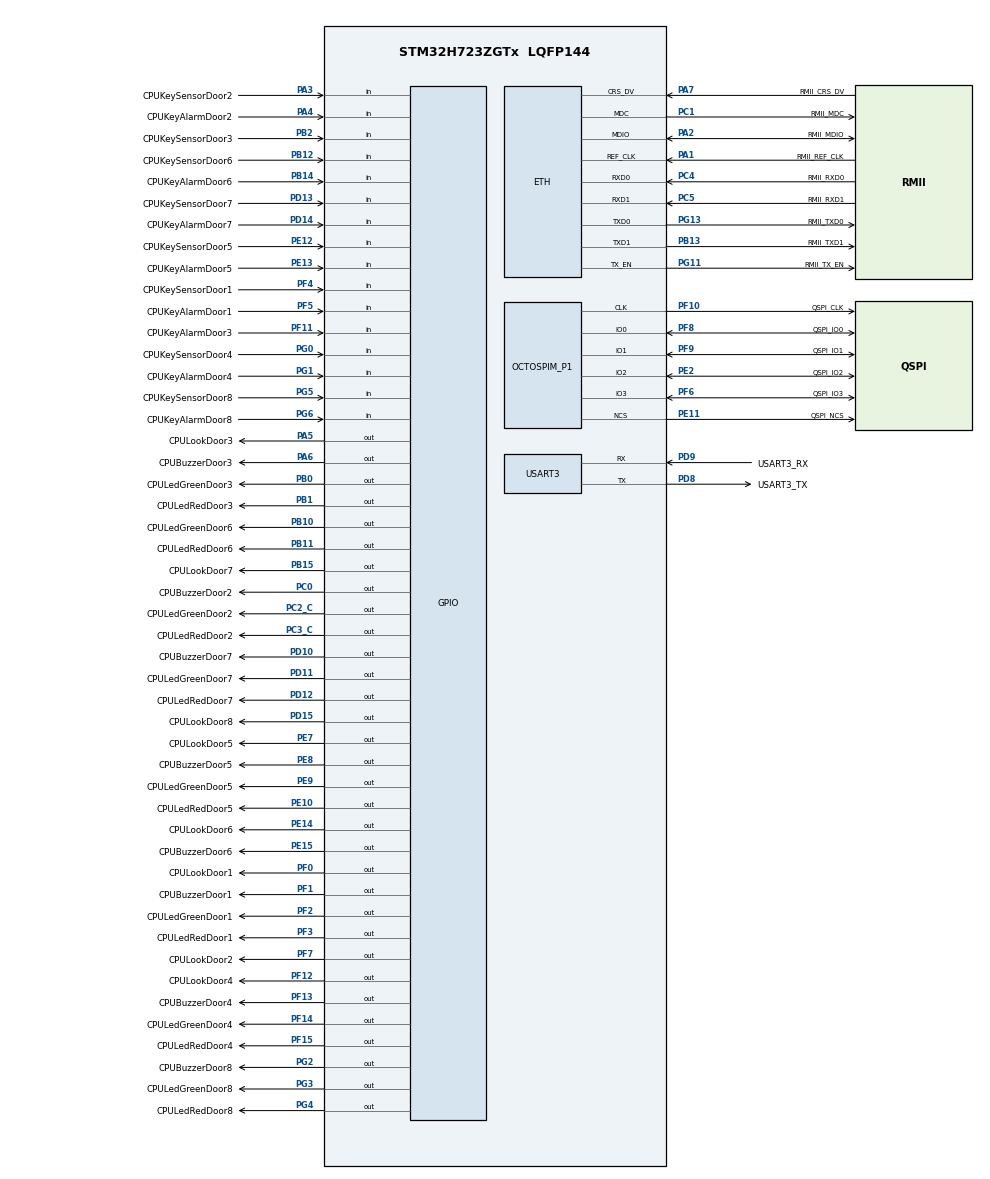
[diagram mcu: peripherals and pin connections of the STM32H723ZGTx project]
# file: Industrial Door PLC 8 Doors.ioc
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CORTEX_M7.AccessPermission_S-Cortex_Memory_Protection_Unit_Region1_Settings_S=MPU_REGION_PRIV_RO
CORTEX_M7.AccessPermission_S-Cortex_Memory_Protection_Unit_Region2_Settings_S=MPU_REGION_FULL_ACCESS
CORTEX_M7.AccessPermission_S-Cortex_Memory_Protection_Unit_Region3_Settings_S=MPU_REGION_FULL_ACCESS
CORTEX_M7.BaseAddress_S-Cortex_Memory_Protection_Unit_Region1_Settings_S=0x08000000
CORTEX_M7.BaseAddress_S-Cortex_Memory_Protection_Unit_Region2_Settings_S=0x24000000
CORTEX_M7.BaseAddress_S-Cortex_Memory_Protection_Unit_Region3_Settings_S=0x30000000
CORTEX_M7.CPU_DCache=Enabled
CORTEX_M7.CPU_ICache=Enabled
CORTEX_M7.DisableExec_S-Cortex_Memory_Protection_Unit_Region2_Settings_S=MPU_INSTRUCTION_ACCESS_DISABLE
CORTEX_M7.Enable_S-Cortex_Memory_Protection_Unit_Region1_Settings_S=MPU_REGION_ENABLE
CORTEX_M7.Enable_S-Cortex_Memory_Protection_Unit_Region2_Settings_S=MPU_REGION_ENABLE
CORTEX_M7.Enable_S-Cortex_Memory_Protection_Unit_Region3_Settings_S=MPU_REGION_ENABLE
CORTEX_M7.IsBufferable_S-Cortex_Memory_Protection_Unit_Region2_Settings_S=MPU_ACCESS_BUFFERABLE
CORTEX_M7.IsCacheable_S-Cortex_Memory_Protection_Unit_Region1_Settings_S=MPU_ACCESS_CACHEABLE
CORTEX_M7.IsCacheable_S-Cortex_Memory_Protection_Unit_Region2_Settings_S=MPU_ACCESS_CACHEABLE
CORTEX_M7.IsShareable_S-Cortex_Memory_Protection_Unit_Region2_Settings_S=MPU_ACCESS_SHAREABLE
CORTEX_M7.Number_S-Cortex_Memory_Protection_Unit_Region2_Settings_S=MPU_REGION_NUMBER2
CORTEX_M7.Number_S-Cortex_Memory_Protection_Unit_Region3_Settings_S=MPU_REGION_NUMBER3
CORTEX_M7.Size_S-Cortex_Memory_Protection_Unit_Region1_Settings_S=MPU_REGION_SIZE_1MB
CORTEX_M7.Size_S-Cortex_Memory_Protection_Unit_Region2_Settings_S=MPU_REGION_SIZE_512KB
CORTEX_M7.Size_S-Cortex_Memory_Protection_Unit_Region3_Settings_S=MPU_REGION_SIZE_32KB
CORTEX_M7.SubRegionDisable_S-Cortex_Memory_Protection_Unit_Region2_Settings_S=0xC0
CORTEX_M7.TypeExtField_S-Cortex_Memory_Protection_Unit_Region1_Settings_S=MPU_TEX_LEVEL1
CORTEX_M7.TypeExtField_S-Cortex_Memory_Protection_Unit_Region2_Settings_S=MPU_TEX_LEVEL1
CORTEX_M7.TypeExtField_S-Cortex_Memory_Protection_Unit_Region3_Settings_S=MPU_TEX_LEVEL1
CORTEX_M7.default_mode_Activation=1
ETH.MediaInterface=HAL_ETH_RMII_MODE
ETH.RxBuffAddress=0x30000200
ETH.RxBuffLen=1536
ETH.TxDescAddress=0x30000100
FREERTOS.Tasks01=netTask,24,768,StartNetTask,Default,NULL,Dynamic,NULL,NULL;commsTask,24,512,StartCommsTask,Default,NULL,Dynamic,NULL,NULL;doorsTask,8,512,StartDoorsTask,Default,NULL,Dynamic,NULL,NULL;supervisorTask,24,512,StartSupervisorTask,Default,NULL,Dynamic,NULL,NULL;httpTask,24,512,StartHttpTask,Default,NULL,Dynamic,NULL,NULL;loggerTask,24,512,StartLoggerTask,Default,NULL,Dynamic,NULL,NULL;watchdogTask,8,512,StartWatchdogTask,Default,NULL,Dynamic,NULL,NULL
FREERTOS.configMINIMAL_STACK_SIZE=128
FREERTOS.configTOTAL_HEAP_SIZE=98304
FREERTOS.configUSE_NEWLIB_REENTRANT=1
LWIP.BSP.number=1
LWIP.GATEWAY_ADDRESS=000.000.000.000
LWIP.IP_ADDRESS=192.168.001.050
LWIP.LWIP_DHCP=0
LWIP.NETMASK_ADDRESS=255.255.255.000
LWIP.Version=v2.1.2_Cube
LWIP0.BSP.STBoard=false
LWIP0.BSP.api=BSP_COMPONENT_DRIVER
LWIP0.BSP.component=LAN8742
LWIP0.BSP.instance=LAN8742
LWIP0.BSP.name=Driver_PHY
LWIP0.BSP.semaphore=S_LAN8742
LWIP0.BSP.solution=LAN8742
Mcu.Family=STM32H7
Mcu.Name=STM32H723ZGTx
Mcu.Package=LQFP144
NVIC.ETH_IRQn=true\:7\:0\:true\:false\:true\:true\:true\:true\:true
NVIC.PriorityGroup=NVIC_PRIORITYGROUP_4
NVIC.TIM6_DAC_IRQn=true\:15\:0\:false\:false\:true\:false\:false\:true\:true
NVIC.TimeBase=TIM6_DAC_IRQn
NVIC.TimeBaseIP=TIM6
NVIC.USART3_IRQn=true\:5\:0\:true\:false\:true\:true\:true\:true\:true
OCTOSPI1.ClockPrescaler=8
OCTOSPI1.DeviceSize=24
OCTOSPI1.MemoryType=HAL_OSPI_MEMTYPE_MACRONIX
PA1.GPIO_Label=RMII_REF_CLK
PA1.GPIO_Speed=GPIO_SPEED_FREQ_VERY_HIGH
PA1.Mode=RMII
PA1.Signal=ETH_REF_CLK
PA11.Signal=FDCAN1_RX
PA12.Signal=FDCAN1_TX
PA13(JTMS/SWDIO).GPIO_Label=SWDIO
PA13(JTMS/SWDIO).Mode=Serial_Wire
PA13(JTMS/SWDIO).Signal=DEBUG_JTMS-SWDIO
PA14(JTCK/SWCLK).GPIO_Label=SWCLK
PA14(JTCK/SWCLK).Mode=Serial_Wire
PA14(JTCK/SWCLK).Signal=DEBUG_JTCK-SWCLK
PA15(JTDI).Signal=UART4_DE
PA2.GPIO_Label=RMII_MDIO
PA2.GPIO_Speed=GPIO_SPEED_FREQ_VERY_HIGH
PA2.Mode=RMII
PA2.Signal=ETH_MDIO
PA3.GPIO_Label=CPUKeySensorDoor2
PA3.GPIO_PuPd=GPIO_PULLUP
PA3.Signal=GPIO_Input
PA4.GPIO_Label=CPUKeyAlarmDoor2
PA4.GPIO_PuPd=GPIO_PULLUP
PA4.Signal=GPIO_Input
PA5.GPIO_Label=CPULookDoor3
PA5.GPIO_PuPd=GPIO_NOPULL
PA5.PinState=GPIO_PIN_SET
PA5.Signal=GPIO_Output
PA6.GPIO_Label=CPUBuzzerDoor3
PA6.GPIO_PuPd=GPIO_NOPULL
PA6.PinState=GPIO_PIN_SET
PA6.Signal=GPIO_Output
PA7.GPIO_Label=RMII_CRS_DV
PA7.GPIO_Speed=GPIO_SPEED_FREQ_VERY_HIGH
PA7.Mode=RMII
PA7.Signal=ETH_CRS_DV
PB0.GPIO_Label=CPULedGreenDoor3
PB0.GPIO_PuPd=GPIO_NOPULL
PB0.PinState=GPIO_PIN_SET
PB0.Signal=GPIO_Output
PB1.GPIO_Label=CPULedRedDoor3
PB1.GPIO_PuPd=GPIO_NOPULL
PB1.PinState=GPIO_PIN_SET
PB1.Signal=GPIO_Output
PB10.GPIO_Label=CPULedGreenDoor6
PB10.GPIO_PuPd=GPIO_NOPULL
PB10.PinState=GPIO_PIN_SET
PB10.Signal=GPIO_Output
PB11.GPIO_Label=CPULedRedDoor6
PB11.GPIO_PuPd=GPIO_NOPULL
PB11.PinState=GPIO_PIN_SET
PB11.Signal=GPIO_Output
PB12.GPIO_Label=CPUKeySensorDoor6
PB12.GPIO_PuPd=GPIO_PULLUP
PB12.Signal=GPIO_Input
PB13.GPIO_Label=RMII_TXD1
PB13.GPIO_Speed=GPIO_SPEED_FREQ_VERY_HIGH
PB13.Mode=RMII
PB13.Signal=ETH_TXD1
PB14.GPIO_Label=CPUKeyAlarmDoor6
PB14.GPIO_PuPd=GPIO_PULLUP
PB14.Signal=GPIO_Input
PB15.GPIO_Label=CPULookDoor7
PB15.GPIO_PuPd=GPIO_NOPULL
PB15.PinState=GPIO_PIN_SET
PB15.Signal=GPIO_Output
PB2.GPIO_Label=CPUKeySensorDoor3
PB2.GPIO_PuPd=GPIO_PULLUP
PB2.Signal=GPIO_Input
PC0.GPIO_Label=CPUBuzzerDoor2
PC0.GPIO_PuPd=GPIO_NOPULL
PC0.PinState=GPIO_PIN_SET
PC0.Signal=GPIO_Output
PC1.GPIO_Label=RMII_MDC
PC1.GPIO_Speed=GPIO_SPEED_FREQ_VERY_HIGH
PC1.Mode=RMII
PC1.Signal=ETH_MDC
PC10.Signal=UART4_TX
PC11.Signal=UART4_RX
PC14-OSC32_IN.GPIO_Label=OSC_IN
PC14-OSC32_IN.Mode=LSE-External-Oscillator
PC14-OSC32_IN.Signal=RCC_OSC32_IN
PC15-OSC32_OUT.GPIO_Label=OSC_OUT
PC15-OSC32_OUT.Mode=LSE-External-Oscillator
PC15-OSC32_OUT.Signal=RCC_OSC32_OUT
PC2_C.GPIO_Label=CPULedGreenDoor2
PC2_C.GPIO_PuPd=GPIO_NOPULL
PC2_C.PinState=GPIO_PIN_SET
PC2_C.Signal=GPIO_Output
PC3_C.GPIO_Label=CPULedRedDoor2
PC3_C.GPIO_PuPd=GPIO_NOPULL
PC3_C.PinState=GPIO_PIN_SET
PC3_C.Signal=GPIO_Output
PC4.GPIO_Label=RMII_RXD0
PC4.GPIO_Speed=GPIO_SPEED_FREQ_VERY_HIGH
PC4.Mode=RMII
PC4.Signal=ETH_RXD0
PC5.GPIO_Label=RMII_RXD1
PC5.GPIO_Speed=GPIO_SPEED_FREQ_VERY_HIGH
PC5.Mode=RMII
PC5.Signal=ETH_RXD1
PD10.GPIO_Label=CPUBuzzerDoor7
PD10.GPIO_PuPd=GPIO_NOPULL
PD10.PinState=GPIO_PIN_SET
PD10.Signal=GPIO_Output
PD11.GPIO_Label=CPULedGreenDoor7
PD11.GPIO_PuPd=GPIO_NOPULL
PD11.PinState=GPIO_PIN_SET
PD11.Signal=GPIO_Output
PD12.GPIO_Label=CPULedRedDoor7
PD12.GPIO_PuPd=GPIO_NOPULL
PD12.PinState=GPIO_PIN_SET
PD12.Signal=GPIO_Output
PD13.GPIO_Label=CPUKeySensorDoor7
PD13.GPIO_PuPd=GPIO_PULLUP
PD13.Signal=GPIO_Input
PD14.GPIO_Label=CPUKeyAlarmDoor7
PD14.GPIO_PuPd=GPIO_PULLUP
PD14.Signal=GPIO_Input
PD15.GPIO_Label=CPULookDoor8
PD15.GPIO_PuPd=GPIO_NOPULL
PD15.PinState=GPIO_PIN_SET
PD15.Signal=GPIO_Output
PD8.GPIO_Label=USART3_TX
PD8.Mode=Asynchronous
PD8.Signal=USART3_TX
PD9.GPIO_Label=USART3_RX
PD9.Mode=Asynchronous
PD9.Signal=USART3_RX
PE10.GPIO_Label=CPULedRedDoor5
PE10.GPIO_PuPd=GPIO_NOPULL
PE10.PinState=GPIO_PIN_SET
PE10.Signal=GPIO_Output
PE11.GPIO_Label=QSPI_NCS
PE11.Mode=OCTOSPI1_Port1_NCS
PE11.Signal=OCTOSPIM_P1_NCS
PE12.GPIO_Label=CPUKeySensorDoor5
PE12.GPIO_PuPd=GPIO_PULLUP
PE12.Signal=GPIO_Input
PE13.GPIO_Label=CPUKeyAlarmDoor5
PE13.GPIO_PuPd=GPIO_PULLUP
PE13.Signal=GPIO_Input
PE14.GPIO_Label=CPULookDoor6
PE14.GPIO_PuPd=GPIO_NOPULL
PE14.PinState=GPIO_PIN_SET
PE14.Signal=GPIO_Output
PE15.GPIO_Label=CPUBuzzerDoor6
PE15.GPIO_PuPd=GPIO_NOPULL
PE15.PinState=GPIO_PIN_SET
PE15.Signal=GPIO_Output
PE2.GPIO_Label=QSPI_IO2
PE2.Mode=OCTOSPI1_IOL_Port1L
PE2.Signal=OCTOSPIM_P1_IO2
PE7.GPIO_Label=CPULookDoor5
PE7.GPIO_PuPd=GPIO_NOPULL
PE7.PinState=GPIO_PIN_SET
PE7.Signal=GPIO_Output
PE8.GPIO_Label=CPUBuzzerDoor5
PE8.GPIO_PuPd=GPIO_NOPULL
PE8.PinState=GPIO_PIN_SET
PE8.Signal=GPIO_Output
PE9.GPIO_Label=CPULedGreenDoor5
PE9.GPIO_PuPd=GPIO_NOPULL
PE9.PinState=GPIO_PIN_SET
PE9.Signal=GPIO_Output
PF0.GPIO_Label=CPULookDoor1
PF0.GPIO_PuPd=GPIO_NOPULL
PF0.PinState=GPIO_PIN_SET
PF0.Signal=GPIO_Output
PF1.GPIO_Label=CPUBuzzerDoor1
PF1.GPIO_PuPd=GPIO_NOPULL
PF1.PinState=GPIO_PIN_SET
PF1.Signal=GPIO_Output
PF10.GPIO_Label=QSPI_CLK
PF10.Mode=O1_P1_CLK
PF10.Signal=OCTOSPIM_P1_CLK
PF11.GPIO_Label=CPUKeyAlarmDoor3
PF11.GPIO_PuPd=GPIO_PULLUP
PF11.Signal=GPIO_Input
PF12.GPIO_Label=CPULookDoor4
PF12.GPIO_PuPd=GPIO_NOPULL
PF12.PinState=GPIO_PIN_SET
PF12.Signal=GPIO_Output
PF13.GPIO_Label=CPUBuzzerDoor4
PF13.GPIO_PuPd=GPIO_NOPULL
PF13.PinState=GPIO_PIN_SET
PF13.Signal=GPIO_Output
PF14.GPIO_Label=CPULedGreenDoor4
PF14.GPIO_PuPd=GPIO_NOPULL
PF14.PinState=GPIO_PIN_SET
PF14.Signal=GPIO_Output
PF15.GPIO_Label=CPULedRedDoor4
PF15.GPIO_PuPd=GPIO_NOPULL
PF15.PinState=GPIO_PIN_SET
PF15.Signal=GPIO_Output
PF2.GPIO_Label=CPULedGreenDoor1
PF2.GPIO_PuPd=GPIO_NOPULL
PF2.PinState=GPIO_PIN_SET
PF2.Signal=GPIO_Output
PF3.GPIO_Label=CPULedRedDoor1
PF3.GPIO_PuPd=GPIO_NOPULL
PF3.PinState=GPIO_PIN_SET
PF3.Signal=GPIO_Output
PF4.GPIO_Label=CPUKeySensorDoor1
PF4.GPIO_PuPd=GPIO_PULLUP
PF4.Signal=GPIO_Input
PF5.GPIO_Label=CPUKeyAlarmDoor1
PF5.GPIO_PuPd=GPIO_PULLUP
PF5.Signal=GPIO_Input
PF6.GPIO_Label=QSPI_IO3
PF6.Mode=OCTOSPI1_IOL_Port1L
PF6.Signal=OCTOSPIM_P1_IO3
PF7.GPIO_Label=CPULookDoor2
PF7.GPIO_PuPd=GPIO_NOPULL
PF7.PinState=GPIO_PIN_SET
PF7.Signal=GPIO_Output
PF8.GPIO_Label=QSPI_IO0
PF8.Mode=OCTOSPI1_IOL_Port1L
PF8.Signal=OCTOSPIM_P1_IO0
PF9.GPIO_Label=QSPI_IO1
PF9.Mode=OCTOSPI1_IOL_Port1L
PF9.Signal=OCTOSPIM_P1_IO1
PG0.GPIO_Label=CPUKeySensorDoor4
PG0.GPIO_PuPd=GPIO_PULLUP
PG0.Signal=GPIO_Input
PG1.GPIO_Label=CPUKeyAlarmDoor4
PG1.GPIO_PuPd=GPIO_PULLUP
PG1.Signal=GPIO_Input
PG11.GPIO_Label=RMII_TX_EN
PG11.GPIO_Speed=GPIO_SPEED_FREQ_VERY_HIGH
PG11.Mode=RMII
PG11.Signal=ETH_TX_EN
PG13.GPIO_Label=RMII_TXD0
PG13.GPIO_Speed=GPIO_SPEED_FREQ_VERY_HIGH
PG13.Mode=RMII
PG13.Signal=ETH_TXD0
PG2.GPIO_Label=CPUBuzzerDoor8
PG2.GPIO_PuPd=GPIO_NOPULL
PG2.PinState=GPIO_PIN_SET
PG2.Signal=GPIO_Output
PG3.GPIO_Label=CPULedGreenDoor8
PG3.GPIO_PuPd=GPIO_NOPULL
PG3.PinState=GPIO_PIN_SET
PG3.Signal=GPIO_Output
PG4.GPIO_Label=CPULedRedDoor8
PG4.GPIO_PuPd=GPIO_NOPULL
PG4.PinState=GPIO_PIN_SET
PG4.Signal=GPIO_Output
PG5.GPIO_Label=CPUKeySensorDoor8
PG5.GPIO_PuPd=GPIO_PULLUP
PG5.Signal=GPIO_Input
PG6.GPIO_Label=CPUKeyAlarmDoor8
PG6.GPIO_PuPd=GPIO_PULLUP
PG6.Signal=GPIO_Input
ProjectManager.HeapSize=0x200
ProjectManager.StackSize=0x400
ProjectManager.TargetToolchain=STM32CubeIDE
RCC.ADCFreq_Value=608000000
RCC.APB1Freq_Value=125000000
RCC.APB2Freq_Value=125000000
RCC.APB3Freq_Value=125000000
RCC.APB4Freq_Value=125000000
RCC.CortexFreq_Value=500000000
RCC.D1PPRE=RCC_APB3_DIV2
RCC.D2PPRE1=RCC_APB1_DIV2
RCC.D2PPRE2=RCC_APB2_DIV2
RCC.D3PPRE=RCC_APB4_DIV2
RCC.DIVM1=4
RCC.DIVM2=1
RCC.DIVN1=31
RCC.DIVN2=19
RCC.DIVP1=1
RCC.DIVQ1=4
RCC.HCLKFreq_Value=250000000
RCC.HPRE=RCC_HCLK_DIV2
RCC.HSE_VALUE=8000000
RCC.PLL2FRACN=0
RCC.PLL3FRACN=0
RCC.PLLFRACN=2048
RCC.SYSCLKFreq_VALUE=500000000
RCC.SYSCLKSource=RCC_SYSCLKSOURCE_PLLCLK
RCC.USBCLockSelection=RCC_USBCLKSOURCE_HSI48
RCC.USBFreq_Value=48000000
USART3.VirtualMode-Asynchronous=VM_ASYNC
VP_FREERTOS_VS_CMSIS_V2.Mode=CMSIS_V2
VP_LWIP_VS_Enabled.Mode=Enabled
VP_MEMORYMAP_VS_MEMORYMAP.Mode=CurAppReg
VP_OCTOSPI1_VS_octo.Mode=octo_mode
VP_SYS_VS_tim6.Mode=TIM6
board=NUCLEO-H723ZG

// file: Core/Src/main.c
/* USER CODE BEGIN Header */
/**
  ******************************************************************************
  * @file           : main.c
  * @brief          : Main program body
  ******************************************************************************
  * @attention
  *
  * Copyright (c) 2025 STMicroelectronics.
  * All rights reserved.
  *
  * This software is licensed under terms that can be found in the LICENSE file
  * in the root directory of this software component.
  * If no LICENSE file comes with this software, it is provided AS-IS.
  *
  ******************************************************************************
  */
/* USER CODE END Header */
#include "main.h"
#include "cmsis_os.h"
#include "lwip.h"
#include "octospi.h"
#include "usart.h"
#include "gpio.h"

/* USER CODE BEGIN Includes */
#include <string.h>

#include <stdio.h>

/* Заголовки в App/system; в makefile есть -I../App/system. Их внутренние #include идут от каталога .h (../config/...). */
#include "config_service.h"
#include "users_service.h"

/* Для временного теста сохранения конфигурации (Этап 7.3). */
#include "FreeRTOS.h"
#include "task.h"

/* USER CODE END Includes */

void SystemClock_Config(void);
static void MPU_Config(void);
void MX_FREERTOS_Init(void);

/* USER CODE BEGIN 0 */

/* --------------------------------------------------------------------------
 * Этап 7.3 (тест атомарного сохранения): временный автосейв через CFG_TEST_SAVE
 *
 * Что делает:
 *  - Если в препроцессоре задано CFG_TEST_SAVE=1, то после старта RTOS
 *    создаётся одноразовая задача, которая через 5 секунд вызывает
 *    ConfigService_Persist() для текущей активной конфигурации в RAM.
 *
 *    Как включить тест (точно по шагам)
 * 1) Включи define
 * STM32CubeIDE → Project Properties →
 * C/C++ Build → Settings → MCU GCC Compiler → Preprocessor → Defined symbols
 * Добавь:
 * CFG_TEST_SAVE=1
 *
 * Зачем:
 *  - На текущем этапе ещё нет CLI/WEB-триггера сохранения.
 *  - Нам нужен детерминированный способ начать цикл persist, чтобы
 *    выполнить power-cut тест (выключить питание во время записи).
 *
 * ВАЖНО:
 *  - В config_storage_qspi.c под CFG_TEST_SAVE добавлены «окна» (HAL_Delay)
 *    между payload и commit-header, чтобы человек успел рубануть питание.
 *  - В релизной сборке просто убери CFG_TEST_SAVE из defines.
 * -------------------------------------------------------------------------- */

#ifdef CFG_TEST_SAVE
extern project_config_t g_project_cfg; /* defined in App/system/config_service.c */

static void cfg_test_uart3_print(const char *s)
{
  if (!s) return;
  (void)HAL_UART_Transmit(&huart3, (uint8_t *)s, (uint16_t)strlen(s), 100);
}

/*
 * Реализация слабого хука из config_storage_qspi.c.
 * Держим здесь (USER CODE), чтобы при регенерации CubeMX не потерялось.
 */
void CfgTestHook_Print(const char *s)
{
  cfg_test_uart3_print(s);
}

static void CfgTestSaveTask(void *argument)
{
  (void)argument;

  cfg_test_uart3_print("CFG_TEST: persist in 5s...\r\n");
  vTaskDelay(pdMS_TO_TICKS(5000));

  cfg_test_uart3_print("CFG_TEST: persist start\r\n");
  const cfg_storage_status_t st = ConfigService_Persist(&g_project_cfg, NULL, 0U);

  char buf[80];
  (void)snprintf(buf, sizeof(buf), "CFG_TEST: persist done st=%u\r\n", (unsigned)st);
  cfg_test_uart3_print(buf);

  vTaskDelete(NULL);
}
#endif

/* USER CODE END 0 */

int main(void)
{

  /* MPU Configuration--------------------------------------------------------*/
  MPU_Config();

  /* Enable the CPU Cache */

  /* Enable I-Cache---------------------------------------------------------*/
  SCB_EnableICache();

  /* Enable D-Cache---------------------------------------------------------*/
  SCB_EnableDCache();

  /* MCU Configuration--------------------------------------------------------*/

  /* Reset of all peripherals, Initializes the Flash interface and the Systick. */
  HAL_Init();

  /* Configure the system clock */
  SystemClock_Config();

  /* Initialize all configured peripherals */
  MX_GPIO_Init();
  MX_USART3_UART_Init();
  MX_OCTOSPI1_Init();
  /* USER CODE BEGIN 2 */

  /* Загрузка конфигурации (MASTER: из QSPI или по умолчанию; SLAVE: по умолчанию) */
  ConfigService_InitOnBoot(0);

  /* Инициализация базы пользователей (MASTER only) */
  UsersService_Init();

#ifdef CFG_TEST_SAVE
  /*
   * Создаём одноразовую задачу автосейва.
   * xTaskCreate допустимо вызывать до старта планировщика.
   */
  (void)xTaskCreate(CfgTestSaveTask, "CfgTestSave", 256, NULL, tskIDLE_PRIORITY + 1U, NULL);
#endif

  /* USER CODE END 2 */

  /* Init scheduler */
  osKernelInitialize();  /* Call init function for freertos objects (in cmsis_os2.c) */
  MX_FREERTOS_Init();

  /* Start scheduler */
  osKernelStart();

  /* We should never get here as control is now taken by the scheduler */

  /* Infinite loop */
  while (1)
  {

  }
}

void SystemClock_Config(void)
{
  RCC_OscInitTypeDef RCC_OscInitStruct = {0};
  RCC_ClkInitTypeDef RCC_ClkInitStruct = {0};

  /** Supply configuration update enable
  */
  HAL_PWREx_ConfigSupply(PWR_LDO_SUPPLY);

  /** Configure the main internal regulator output voltage
  */
  __HAL_PWR_VOLTAGESCALING_CONFIG(PWR_REGULATOR_VOLTAGE_SCALE0);

  while(!__HAL_PWR_GET_FLAG(PWR_FLAG_VOSRDY)) {}

  /** Initializes the RCC Oscillators according to the specified parameters
  * in the RCC_OscInitTypeDef structure.
  */
  RCC_OscInitStruct.OscillatorType = RCC_OSCILLATORTYPE_HSI;
  RCC_OscInitStruct.HSIState = RCC_HSI_DIV1;
  RCC_OscInitStruct.HSICalibrationValue = 64;
  RCC_OscInitStruct.PLL.PLLState = RCC_PLL_ON;
  RCC_OscInitStruct.PLL.PLLSource = RCC_PLLSOURCE_HSI;
  RCC_OscInitStruct.PLL.PLLM = 4;
  RCC_OscInitStruct.PLL.PLLN = 31;
  RCC_OscInitStruct.PLL.PLLP = 1;
  RCC_OscInitStruct.PLL.PLLQ = 4;
  RCC_OscInitStruct.PLL.PLLR = 2;
  RCC_OscInitStruct.PLL.PLLRGE = RCC_PLL1VCIRANGE_3;
  RCC_OscInitStruct.PLL.PLLVCOSEL = RCC_PLL1VCOWIDE;
  RCC_OscInitStruct.PLL.PLLFRACN = 2048;
  if (HAL_RCC_OscConfig(&RCC_OscInitStruct) != HAL_OK)
  {
    Error_Handler();
  }

  /** Initializes the CPU, AHB and APB buses clocks
  */
  RCC_ClkInitStruct.ClockType = RCC_CLOCKTYPE_HCLK|RCC_CLOCKTYPE_SYSCLK
                              |RCC_CLOCKTYPE_PCLK1|RCC_CLOCKTYPE_PCLK2
                              |RCC_CLOCKTYPE_D3PCLK1|RCC_CLOCKTYPE_D1PCLK1;
  RCC_ClkInitStruct.SYSCLKSource = RCC_SYSCLKSOURCE_PLLCLK;
  RCC_ClkInitStruct.SYSCLKDivider = RCC_SYSCLK_DIV1;
  RCC_ClkInitStruct.AHBCLKDivider = RCC_HCLK_DIV2;
  RCC_ClkInitStruct.APB3CLKDivider = RCC_APB3_DIV2;
  RCC_ClkInitStruct.APB1CLKDivider = RCC_APB1_DIV2;
  RCC_ClkInitStruct.APB2CLKDivider = RCC_APB2_DIV2;
  RCC_ClkInitStruct.APB4CLKDivider = RCC_APB4_DIV2;

  if (HAL_RCC_ClockConfig(&RCC_ClkInitStruct, FLASH_LATENCY_3) != HAL_OK)
  {
    Error_Handler();
  }
}

 /* MPU Configuration */

void MPU_Config(void)
{
  MPU_Region_InitTypeDef MPU_InitStruct = {0};

  /* Disables the MPU */
  HAL_MPU_Disable();

  /** Initializes and configures the Region and the memory to be protected
  */
  MPU_InitStruct.Enable = MPU_REGION_ENABLE;
  MPU_InitStruct.Number = MPU_REGION_NUMBER0;
  MPU_InitStruct.BaseAddress = 0x0;
  MPU_InitStruct.Size = MPU_REGION_SIZE_4GB;
  MPU_InitStruct.SubRegionDisable = 0x87;
  MPU_InitStruct.TypeExtField = MPU_TEX_LEVEL0;
  MPU_InitStruct.AccessPermission = MPU_REGION_NO_ACCESS;
  MPU_InitStruct.DisableExec = MPU_INSTRUCTION_ACCESS_DISABLE;
  MPU_InitStruct.IsShareable = MPU_ACCESS_SHAREABLE;
  MPU_InitStruct.IsCacheable = MPU_ACCESS_NOT_CACHEABLE;
  MPU_InitStruct.IsBufferable = MPU_ACCESS_NOT_BUFFERABLE;

  HAL_MPU_ConfigRegion(&MPU_InitStruct);

  /** Initializes and configures the Region and the memory to be protected
  */
  MPU_InitStruct.Number = MPU_REGION_NUMBER1;
  MPU_InitStruct.BaseAddress = 0x08000000;
  MPU_InitStruct.Size = MPU_REGION_SIZE_1MB;
  MPU_InitStruct.SubRegionDisable = 0x0;
  MPU_InitStruct.TypeExtField = MPU_TEX_LEVEL1;
  MPU_InitStruct.AccessPermission = MPU_REGION_PRIV_RO;
  MPU_InitStruct.DisableExec = MPU_INSTRUCTION_ACCESS_ENABLE;
  MPU_InitStruct.IsShareable = MPU_ACCESS_NOT_SHAREABLE;
  MPU_InitStruct.IsCacheable = MPU_ACCESS_CACHEABLE;

  HAL_MPU_ConfigRegion(&MPU_InitStruct);

  /** Initializes and configures the Region and the memory to be protected
  */
  MPU_InitStruct.Number = MPU_REGION_NUMBER2;
  MPU_InitStruct.BaseAddress = 0x24000000;
  MPU_InitStruct.Size = MPU_REGION_SIZE_512KB;
  MPU_InitStruct.SubRegionDisable = 0xC0;
  MPU_InitStruct.AccessPermission = MPU_REGION_FULL_ACCESS;
  MPU_InitStruct.DisableExec = MPU_INSTRUCTION_ACCESS_DISABLE;
  MPU_InitStruct.IsShareable = MPU_ACCESS_SHAREABLE;
  MPU_InitStruct.IsBufferable = MPU_ACCESS_BUFFERABLE;

  HAL_MPU_ConfigRegion(&MPU_InitStruct);

  /** Initializes and configures the Region and the memory to be protected
  */
  MPU_InitStruct.Number = MPU_REGION_NUMBER3;
  MPU_InitStruct.BaseAddress = 0x30000000;
  MPU_InitStruct.Size = MPU_REGION_SIZE_32KB;
  MPU_InitStruct.SubRegionDisable = 0x0;
  MPU_InitStruct.DisableExec = MPU_INSTRUCTION_ACCESS_ENABLE;
  MPU_InitStruct.IsShareable = MPU_ACCESS_NOT_SHAREABLE;
  MPU_InitStruct.IsCacheable = MPU_ACCESS_NOT_CACHEABLE;
  MPU_InitStruct.IsBufferable = MPU_ACCESS_NOT_BUFFERABLE;

  HAL_MPU_ConfigRegion(&MPU_InitStruct);
  /* Enables the MPU */
  HAL_MPU_Enable(MPU_PRIVILEGED_DEFAULT);

}

void HAL_TIM_PeriodElapsedCallback(TIM_HandleTypeDef *htim)
{
  if (htim->Instance == TIM6)
  {
    HAL_IncTick();
  }
}

void Error_Handler(void)
{
  __disable_irq();
  while (1)
  {
  }
}

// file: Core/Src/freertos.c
/* USER CODE BEGIN Header */
/**
  ******************************************************************************
  * @file    freertos.c
  * @brief   RTOS stage-2 skeleton (full plan: tasks + event bus + supervisor + watchdog)
  *
  * ЭТАП 2 по плану:
  * 2.1 FreeRTOS + CMSIS-OS
 * 2.2 Декомпозиция задач (упрощённая одноплатная сборка):
 *   - DOOR TASK
 *   - LOGIC CORE TASK (commsTask)
 *   - ETHERNET/HTTP TASK
 *   - LOGGER
 *   - WATCHDOG/SUPERVISOR TASK
 *   Задач CAN и RS-485 в RTOS нет (одноплатная прошивка, только локальные двери и Ethernet).
  * 2.3 Межзадачное взаимодействие: очередь событий + очередь логов
  * 2.4 Базовый watchdog + контроль зависаний: Health/Heartbeat + Supervisor/Watchdog
  *
  * ВАЖНО:
  * - Никакие модули (LwIP bring-up и т.п.) НЕ создают задачи изнутри.
  * - Все osThreadCreate() только здесь.
  ******************************************************************************
  */
/* USER CODE END Header */

#include "FreeRTOS.h"
#include "task.h"
#include "main.h"
#include "cmsis_os.h"

/* USER CODE BEGIN Includes */
#include "usart.h"
#include "app_events.h"
#include "app_health.h"
#include "app_log.h"

/* App/doors — относительно Core/Src (см. комментарий в main.c про subdir.mk / -I../App). */
#include "../../App/doors/doors_task.h"

/* App/system */
#include "comms_task.h"
#include "net_task.h"
#include "supervisor_task.h"
#include "http_task.h"
#include "http_server.h"
#include "logger_task.h"
#include "watchdog_task.h"
#include "log/event_journal.h"
#include "stdio.h"
#include <stdint.h>
extern volatile uint32_t g_eth_irq;
extern volatile uint32_t g_eth_rx_cb;
extern volatile uint32_t g_eth_tx_cb;
extern volatile uint32_t g_eth_tcpip_cb_fail;

/* USER CODE END Includes */

/* Definitions for netTask */
osThreadId_t netTaskHandle;
const osThreadAttr_t netTask_attributes = {
  .name = "netTask",
  .stack_size = 768 * 4,
  /* Выше httpTask: сначала MX_LWIP_Init(), иначе httpTask теоретически может опередить и дергать gnetif до готовности. */
  .priority = (osPriority_t) osPriorityAboveNormal,
};
/* Definitions for commsTask */
osThreadId_t commsTaskHandle;
const osThreadAttr_t commsTask_attributes = {
  .name = "commsTask",
  .stack_size = 512 * 4,
  .priority = (osPriority_t) osPriorityNormal,
};
/* Definitions for doorsTask */
osThreadId_t doorsTaskHandle;
const osThreadAttr_t doorsTask_attributes = {
  .name = "doorsTask",
  .stack_size = 512 * 4,
  .priority = (osPriority_t) osPriorityLow,
};
/* Definitions for supervisorTask */
osThreadId_t supervisorTaskHandle;
const osThreadAttr_t supervisorTask_attributes = {
  .name = "supervisorTask",
  .stack_size = 512 * 4,
  .priority = (osPriority_t) osPriorityNormal,
};
/* Definitions for httpTask */
osThreadId_t httpTaskHandle;
const osThreadAttr_t httpTask_attributes = {
  .name = "httpTask",
  /* stack_size в CMSIS-RTOS v2 — байты. На стеке httpTask буфер GET (HTTP_GET_RESPONSE_MAX, до ~12 КБ)
   * плюс цепочка HttpApi_HandleGet — малый стек даёт переполнение и обрывы TCP. */
  .stack_size = 32u * 1024u,
  .priority = (osPriority_t) osPriorityNormal,
};
/* Definitions for loggerTask */
osThreadId_t loggerTaskHandle;
const osThreadAttr_t loggerTask_attributes = {
  .name = "loggerTask",
  .stack_size = 512 * 4,
  .priority = (osPriority_t) osPriorityNormal,
};
/* Definitions for watchdogTask */
osThreadId_t watchdogTaskHandle;
const osThreadAttr_t watchdogTask_attributes = {
  .name = "watchdogTask",
  .stack_size = 512 * 4,
  .priority = (osPriority_t) osPriorityLow,
};
/* USER CODE BEGIN FunctionPrototypes */
static void TaskShouldNeverReturn(void);
/* USER CODE END FunctionPrototypes */

void StartNetTask(void *argument);
void StartCommsTask(void *argument);
void StartDoorsTask(void *argument);
void StartSupervisorTask(void *argument);
void StartHttpTask(void *argument);
void StartLoggerTask(void *argument);
void StartWatchdogTask(void *argument);
extern void MX_LWIP_Init(void);
void MX_FREERTOS_Init(void); /* (MISRA C 2004 rule 8.1) */

void MX_FREERTOS_Init(void) {
  /* USER CODE BEGIN Init */
  AppEvents_Init();
  AppHealth_Init();
  AppLog_Init();
  /* Журнал событий на QSPI отключён (без задачи и очереди); инициализируем только QSPI-lock и метаданные для EraseAll. */
  EventJournal_Init();
  /* USER CODE END Init */

  /* USER CODE BEGIN RTOS_QUEUES */
  /* queues are initialized in AppEvents/AppLog */
  /* USER CODE END RTOS_QUEUES */

  /* Create the thread(s) */
  /* creation of netTask */
  netTaskHandle = osThreadNew(StartNetTask, NULL, &netTask_attributes);

  /* creation of commsTask */
  commsTaskHandle = osThreadNew(StartCommsTask, NULL, &commsTask_attributes);

  /* creation of doorsTask */
  doorsTaskHandle = osThreadNew(StartDoorsTask, NULL, &doorsTask_attributes);

  /* creation of supervisorTask */
  supervisorTaskHandle = osThreadNew(StartSupervisorTask, NULL, &supervisorTask_attributes);

  /* creation of httpTask */
  httpTaskHandle = osThreadNew(StartHttpTask, NULL, &httpTask_attributes);

  /* creation of loggerTask */
  loggerTaskHandle = osThreadNew(StartLoggerTask, NULL, &loggerTask_attributes);

  /* creation of watchdogTask */
  watchdogTaskHandle = osThreadNew(StartWatchdogTask, NULL, &watchdogTask_attributes);

}

void StartNetTask(void *argument)
{
  /* init code for LWIP */
  MX_LWIP_Init();
  /* USER CODE BEGIN StartNetTask */
  /* Если хочешь задержку "до" LWIP init — её нельзя ставить здесь,
     потому что MX_LWIP_Init() находится в автогенерируемом блоке выше. */
  printf("ETH: irq=%lu rxcb=%lu txcb=%lu tcpipcbf=%lu httpsel=%lu httpacc=%lu listen=%u\n",
         g_eth_irq, g_eth_rx_cb, g_eth_tx_cb,
         g_eth_tcpip_cb_fail, g_http_listen_sel_fail, g_http_accept_fail,
         (unsigned)HttpServer_IsReady());

  NetTask_Run(argument);

  configASSERT(0);
  TaskShouldNeverReturn();
  /* USER CODE END StartNetTask */
}

void StartCommsTask(void *argument)
{
  /* USER CODE BEGIN StartCommsTask */
  CommsTask_Run(argument);

  configASSERT(0);
  TaskShouldNeverReturn();
  /* USER CODE END StartCommsTask */
}

void StartDoorsTask(void *argument)
{
  /* USER CODE BEGIN StartDoorsTask */
  DoorsTask_Run(argument);

  configASSERT(0);
  TaskShouldNeverReturn();
  /* USER CODE END StartDoorsTask */
}

void StartSupervisorTask(void *argument)
{
  /* USER CODE BEGIN StartSupervisorTask */
  SupervisorTask_Run(argument);

  configASSERT(0);
  TaskShouldNeverReturn();
  /* USER CODE END StartSupervisorTask */
}

void StartHttpTask(void *argument)
{
  /* USER CODE BEGIN StartHttpTask */

  HttpTask_Run(argument);

  configASSERT(0);
  TaskShouldNeverReturn();
  /* USER CODE END StartHttpTask */
}

void StartLoggerTask(void *argument)
{
  /* USER CODE BEGIN StartLoggerTask */
  LoggerTask_Run(argument);

  configASSERT(0);
  TaskShouldNeverReturn();
  /* USER CODE END StartLoggerTask */
}

void StartWatchdogTask(void *argument)
{
  /* USER CODE BEGIN StartWatchdogTask */
  WatchdogTask_Run(argument);

  configASSERT(0);
  TaskShouldNeverReturn();
  /* USER CODE END StartWatchdogTask */
}

/* USER CODE BEGIN Application */
/* Эта функция нужна как "предохранитель":
 * все Start*Task() вызывают реальные Run()-функции задач,
 * которые никогда не должны возвращаться.
 * Если вернулись — это фатальная логическая ошибка.
 */
static void TaskShouldNeverReturn(void)
{
  taskDISABLE_INTERRUPTS();
  for (;;)
  {
    /* dead loop */
  }
}
/* USER CODE END Application */
